NS_ :

BS_:

BU_: VCU BMS DD MM5 PDM MM52 RAND

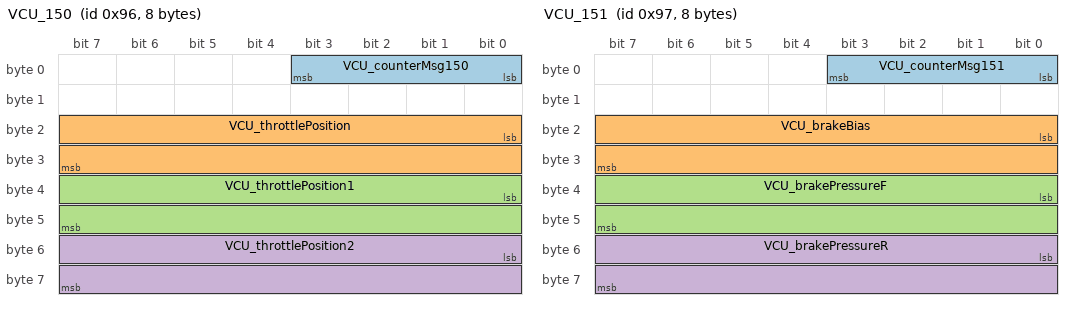
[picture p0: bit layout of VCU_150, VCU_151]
BO_ 150 VCU_150: 8 VCU
 SG_ VCU_counterMsg150 : 0|4@1+ (1,0) [0|15] "" Vector__XXX
 SG_ VCU_throttlePosition : 16|16@1- (0.1,0) [0|100] "%" Vector__XXX
 SG_ VCU_throttlePosition1 : 32|16@1- (0.1,0) [0|100] "%" Vector__XXX
 SG_ VCU_throttlePosition2 : 48|16@1- (0.1,0) [0|100] "%" Vector__XXX

BO_ 151 VCU_151: 8 VCU
 SG_ VCU_counterMsg151 : 0|4@1+ (1,0) [0|15] "" Vector__XXX
 SG_ VCU_brakeBias : 16|16@1- (0.1,0) [-3276.8|3276.7] "%" Vector__XXX
 SG_ VCU_brakePressureF : 32|16@1- (0.1,0) [0|2000] "psi" Vector__XXX
 SG_ VCU_brakePressureR : 48|16@1- (0.1,0) [0|2000] "psi" Vector__XXX

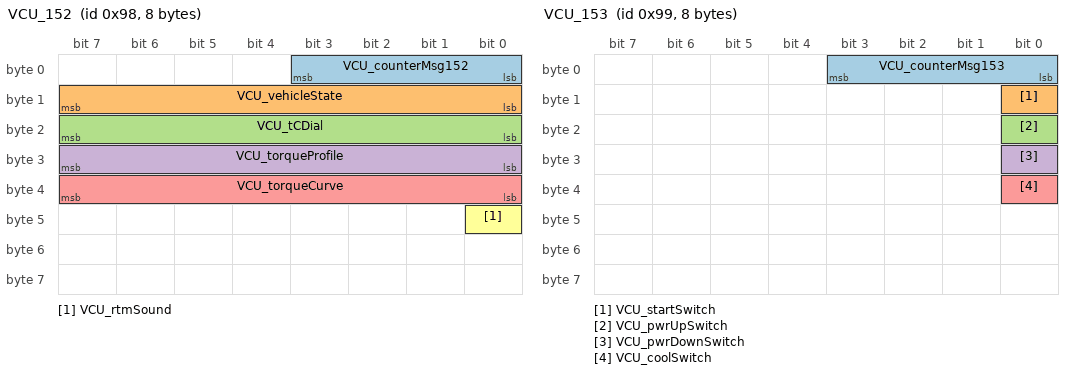
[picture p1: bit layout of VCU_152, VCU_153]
BO_ 152 VCU_152: 8 VCU
 SG_ VCU_counterMsg152 : 0|4@1+ (1,0) [0|15] "" Vector__XXX
 SG_ VCU_vehicleState : 8|8@1+ (1,0) [0|255] "" Vector__XXX
 SG_ VCU_tCDial : 16|8@1+ (1,0) [0|255] "" Vector__XXX
 SG_ VCU_torqueProfile : 24|8@1+ (1,0) [0|255] "" Vector__XXX
 SG_ VCU_torqueCurve : 32|8@1+ (1,0) [0|255] "" Vector__XXX
 SG_ VCU_rtmSound : 40|1@1+ (1,0) [0|1] "" Vector__XXX

BO_ 153 VCU_153: 8 VCU
 SG_ VCU_counterMsg153 : 0|4@1+ (1,0) [0|15] "" Vector__XXX
 SG_ VCU_startSwitch : 8|1@1+ (1,0) [0|1] "" Vector__XXX
 SG_ VCU_pwrUpSwitch : 16|1@1+ (1,0) [0|1] "" Vector__XXX
 SG_ VCU_pwrDownSwitch : 24|1@1+ (1,0) [0|1] "" Vector__XXX
 SG_ VCU_coolSwitch : 32|1@1+ (1,0) [0|1] "" Vector__XXX

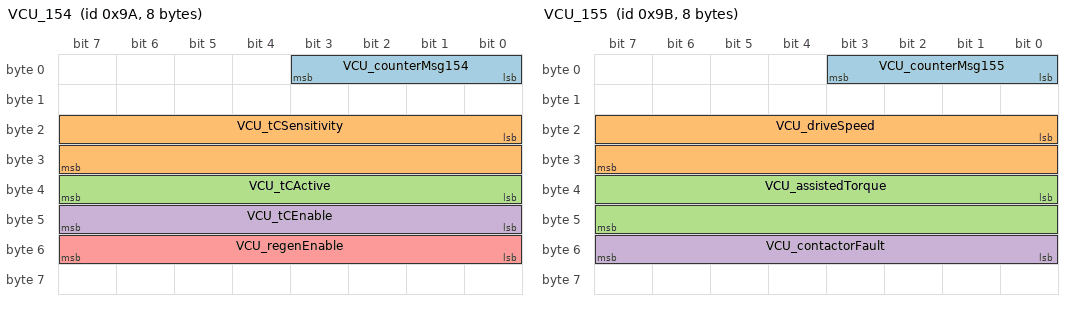
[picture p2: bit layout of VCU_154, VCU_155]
BO_ 154 VCU_154: 8 VCU
 SG_ VCU_counterMsg154 : 0|4@1+ (1,0) [0|15] "" Vector__XXX
 SG_ VCU_tCSensitivity : 16|16@1+ (1,0) [-20|3276.7] "" Vector__XXX
 SG_ VCU_tCActive : 32|8@1+ (1,0) [0|255] "" Vector__XXX
 SG_ VCU_tCEnable : 40|8@1+ (1,0) [0|255] "" Vector__XXX
 SG_ VCU_regenEnable : 48|8@1+ (1,0) [0|255] "" Vector__XXX

BO_ 155 VCU_155: 8 VCU
 SG_ VCU_counterMsg155 : 0|4@1+ (1,0) [0|15] "" Vector__XXX
 SG_ VCU_driveSpeed : 16|16@1- (0.1,0) [-20|3276.7] "mph" Vector__XXX
 SG_ VCU_assistedTorque : 32|16@1- (0.1,0) [-300|300] "Nm" Vector__XXX
 SG_ VCU_contactorFault : 48|8@1+ (1,0) [0|255] "" Vector__XXX

BO_ 156 VCU_156: 8 VCU
 SG_ VCU_counterMsg156 : 0|4@1+ (1,0) [0|15] "" Vector__XXX

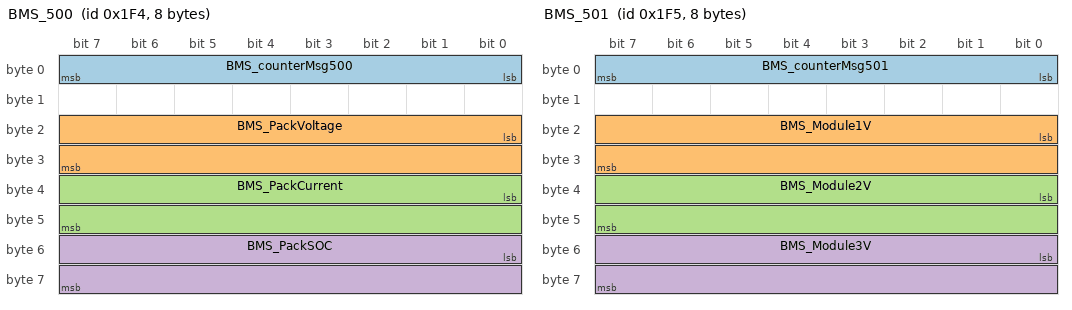
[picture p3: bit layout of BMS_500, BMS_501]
BO_ 500 BMS_500: 8 BMS
 SG_ BMS_counterMsg500 : 0|8@1+ (1,0) [0|15] "" Vector__XXX
 SG_ BMS_PackVoltage : 16|16@1+ (1,0) [-3276|3276] "V" Vector__XXX
 SG_ BMS_PackCurrent : 32|16@1+ (1,0) [-3276|3276] "A" Vector__XXX
 SG_ BMS_PackSOC : 48|16@1+ (1,0) [0|15] "%" Vector__XXX

BO_ 501 BMS_501: 8 BMS
 SG_ BMS_counterMsg501 : 0|8@1+ (1,0) [0|15] "" Vector__XXX
 SG_ BMS_Module1V : 16|16@1+ (1,0) [-3276|3276] "V" Vector__XXX
 SG_ BMS_Module2V : 32|16@1+ (1,0) [-3276|3276] "V" Vector__XXX
 SG_ BMS_Module3V : 48|16@1+ (1,0) [-3276|3276] "V" Vector__XXX

BO_ 502 BMS_502: 8 BMS
 SG_ BMS_counterMsg502 : 0|8@1+ (1,0) [0|15] "" Vector__XXX
 SG_ BMS_Module4V : 16|16@1+ (1,0) [-3276|3276] "V" Vector__XXX
 SG_ BMS_Module5V : 32|16@1+ (1,0) [-3276|3276] "V" Vector__XXX

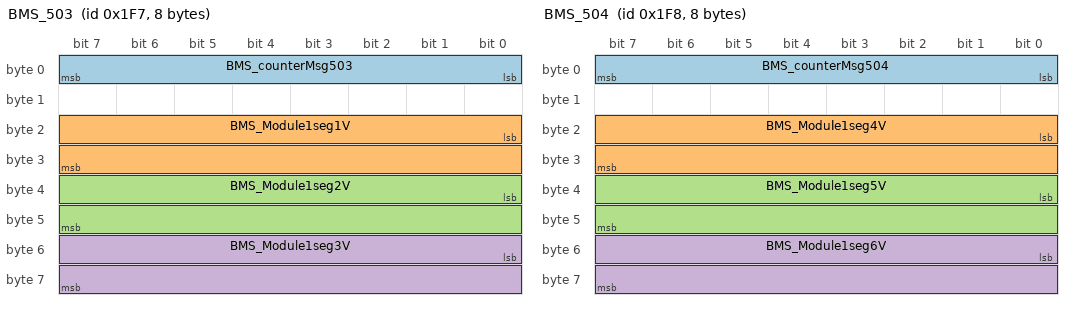
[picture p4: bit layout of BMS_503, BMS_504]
BO_ 503 BMS_503: 8 BMS
 SG_ BMS_counterMsg503 : 0|8@1+ (1,0) [0|15] "" Vector__XXX
 SG_ BMS_Module1seg1V : 16|16@1+ (1,0) [-3276|3276] "V" Vector__XXX
 SG_ BMS_Module1seg2V : 32|16@1+ (1,0) [-3276|3276] "V" Vector__XXX
 SG_ BMS_Module1seg3V : 48|16@1+ (1,0) [-3276|3276] "V" Vector__XXX

BO_ 504 BMS_504: 8 BMS
 SG_ BMS_counterMsg504 : 0|8@1+ (1,0) [0|15] "" Vector__XXX
 SG_ BMS_Module1seg4V : 16|16@1+ (1,0) [-3276|3276] "V" Vector__XXX
 SG_ BMS_Module1seg5V : 32|16@1+ (1,0) [-3276|3276] "V" Vector__XXX
 SG_ BMS_Module1seg6V : 48|16@1+ (1,0) [-3276|3276] "V" Vector__XXX

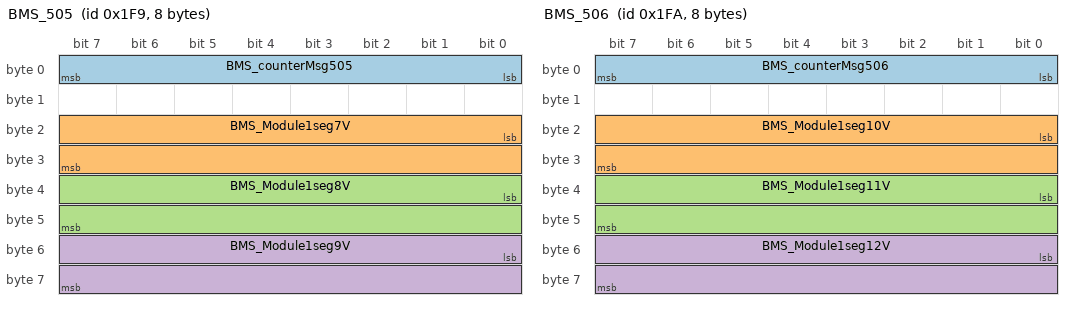
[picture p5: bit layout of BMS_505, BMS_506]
BO_ 505 BMS_505: 8 BMS
 SG_ BMS_counterMsg505 : 0|8@1+ (1,0) [0|15] "" Vector__XXX
 SG_ BMS_Module1seg7V : 16|16@1+ (1,0) [-3276|3276] "V" Vector__XXX
 SG_ BMS_Module1seg8V : 32|16@1+ (1,0) [-3276|3276] "V" Vector__XXX
 SG_ BMS_Module1seg9V : 48|16@1+ (1,0) [-3276|3276] "V" Vector__XXX

BO_ 506 BMS_506: 8 BMS
 SG_ BMS_counterMsg506 : 0|8@1+ (1,0) [0|15] "" Vector__XXX
 SG_ BMS_Module1seg10V : 16|16@1+ (1,0) [-3276|3276] "V" Vector__XXX
 SG_ BMS_Module1seg11V : 32|16@1+ (1,0) [-3276|3276] "V" Vector__XXX
 SG_ BMS_Module1seg12V : 48|16@1+ (1,0) [-3276|3276] "V" Vector__XXX

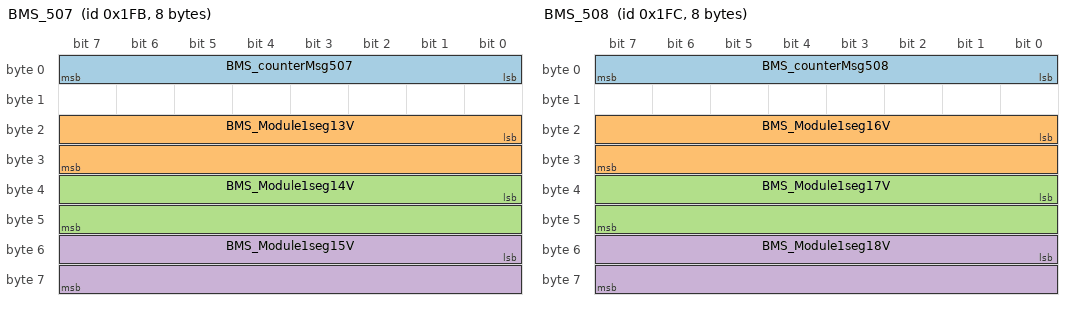
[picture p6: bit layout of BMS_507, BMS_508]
BO_ 507 BMS_507: 8 BMS
 SG_ BMS_counterMsg507 : 0|8@1+ (1,0) [0|15] "" Vector__XXX
 SG_ BMS_Module1seg13V : 16|16@1+ (1,0) [-3276|3276] "V" Vector__XXX
 SG_ BMS_Module1seg14V : 32|16@1+ (1,0) [-3276|3276] "V" Vector__XXX
 SG_ BMS_Module1seg15V : 48|16@1+ (1,0) [-3276|3276] "V" Vector__XXX

BO_ 508 BMS_508: 8 BMS
 SG_ BMS_counterMsg508 : 0|8@1+ (1,0) [0|15] "" Vector__XXX
 SG_ BMS_Module1seg16V : 16|16@1+ (1,0) [-3276|3276] "V" Vector__XXX
 SG_ BMS_Module1seg17V : 32|16@1+ (1,0) [-3276|3276] "V" Vector__XXX
 SG_ BMS_Module1seg18V : 48|16@1+ (1,0) [-3276|3276] "V" Vector__XXX

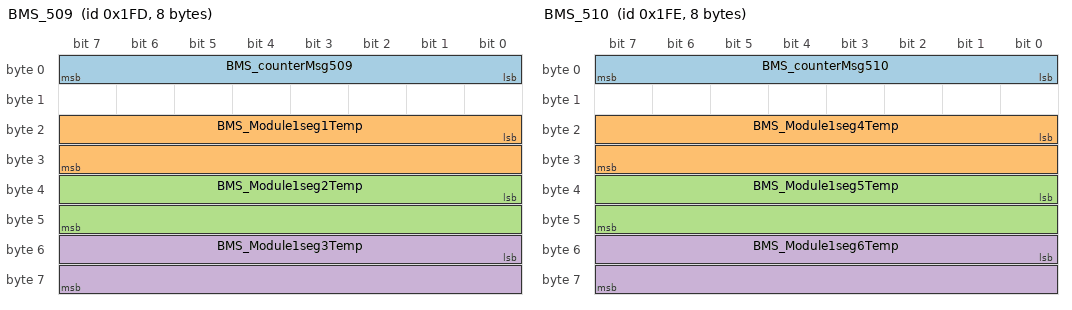
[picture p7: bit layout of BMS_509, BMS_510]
BO_ 509 BMS_509: 8 BMS
 SG_ BMS_counterMsg509 : 0|8@1+ (1,0) [0|15] "" Vector__XXX
 SG_ BMS_Module1seg1Temp : 16|16@1+ (1,0) [-3276|3276] "C" Vector__XXX
 SG_ BMS_Module1seg2Temp : 32|16@1+ (1,0) [-3276|3276] "C" Vector__XXX
 SG_ BMS_Module1seg3Temp : 48|16@1+ (1,0) [-3276|3276] "C" Vector__XXX

BO_ 510 BMS_510: 8 BMS
 SG_ BMS_counterMsg510 : 0|8@1+ (1,0) [0|15] "" Vector__XXX
 SG_ BMS_Module1seg4Temp : 16|16@1+ (1,0) [-3276|3276] "C" Vector__XXX
 SG_ BMS_Module1seg5Temp : 32|16@1+ (1,0) [-3276|3276] "C" Vector__XXX
 SG_ BMS_Module1seg6Temp : 48|16@1+ (1,0) [-3276|3276] "C" Vector__XXX

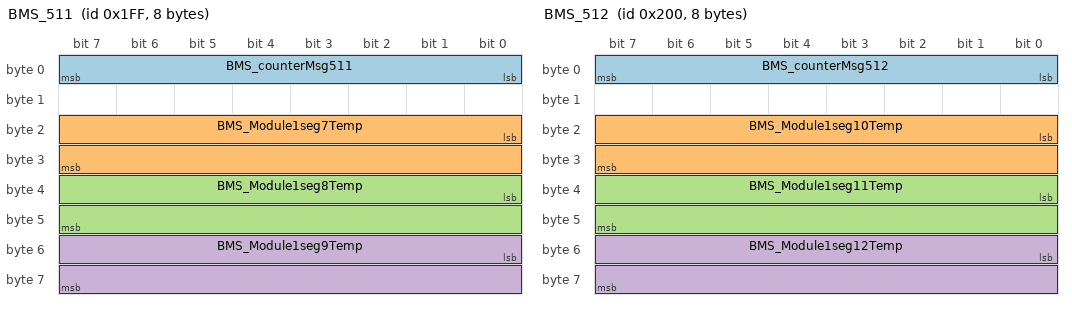
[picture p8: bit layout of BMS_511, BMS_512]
BO_ 511 BMS_511: 8 BMS
 SG_ BMS_counterMsg511 : 0|8@1+ (1,0) [0|15] "" Vector__XXX
 SG_ BMS_Module1seg7Temp : 16|16@1+ (1,0) [-3276|3276] "C" Vector__XXX
 SG_ BMS_Module1seg8Temp : 32|16@1+ (1,0) [-3276|3276] "C" Vector__XXX
 SG_ BMS_Module1seg9Temp : 48|16@1+ (1,0) [-3276|3276] "C" Vector__XXX

BO_ 512 BMS_512: 8 BMS
 SG_ BMS_counterMsg512 : 0|8@1+ (1,0) [0|15] "" Vector__XXX
 SG_ BMS_Module1seg10Temp : 16|16@1+ (1,0) [-3276|3276] "C" Vector__XXX
 SG_ BMS_Module1seg11Temp : 32|16@1+ (1,0) [-3276|3276] "C" Vector__XXX
 SG_ BMS_Module1seg12Temp : 48|16@1+ (1,0) [-3276|3276] "C" Vector__XXX

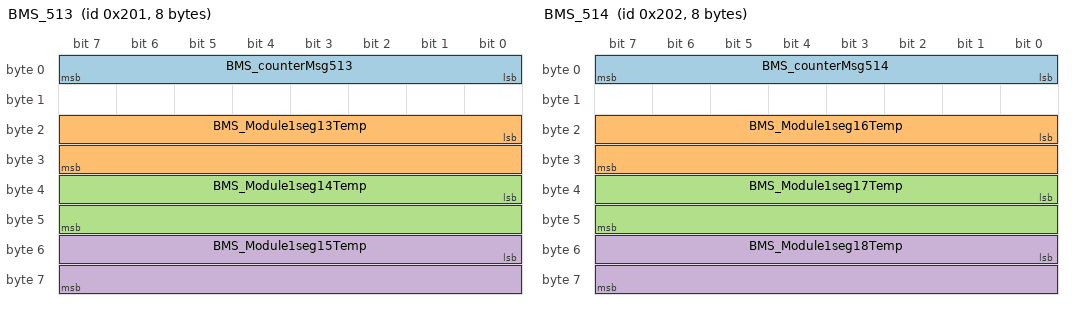
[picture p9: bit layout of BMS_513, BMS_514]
BO_ 513 BMS_513: 8 BMS
 SG_ BMS_counterMsg513 : 0|8@1+ (1,0) [0|15] "" Vector__XXX
 SG_ BMS_Module1seg13Temp : 16|16@1+ (1,0) [-3276|3276] "C" Vector__XXX
 SG_ BMS_Module1seg14Temp : 32|16@1+ (1,0) [-3276|3276] "C" Vector__XXX
 SG_ BMS_Module1seg15Temp : 48|16@1+ (1,0) [-3276|3276] "C" Vector__XXX

BO_ 514 BMS_514: 8 BMS
 SG_ BMS_counterMsg514 : 0|8@1+ (1,0) [0|15] "" Vector__XXX
 SG_ BMS_Module1seg16Temp : 16|16@1+ (1,0) [-3276|3276] "C" Vector__XXX
 SG_ BMS_Module1seg17Temp : 32|16@1+ (1,0) [-3276|3276] "C" Vector__XXX
 SG_ BMS_Module1seg18Temp : 48|16@1+ (1,0) [-3276|3276] "C" Vector__XXX

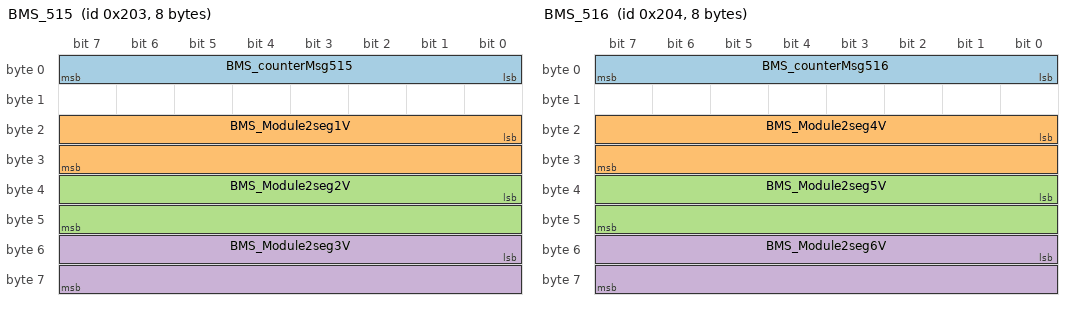
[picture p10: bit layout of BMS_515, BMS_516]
BO_ 515 BMS_515: 8 BMS
 SG_ BMS_counterMsg515 : 0|8@1+ (1,0) [0|15] "" Vector__XXX
 SG_ BMS_Module2seg1V : 16|16@1+ (1,0) [-3276|3276] "V" Vector__XXX
 SG_ BMS_Module2seg2V : 32|16@1+ (1,0) [-3276|3276] "V" Vector__XXX
 SG_ BMS_Module2seg3V : 48|16@1+ (1,0) [-3276|3276] "V" Vector__XXX

BO_ 516 BMS_516: 8 BMS
 SG_ BMS_counterMsg516 : 0|8@1+ (1,0) [0|15] "" Vector__XXX
 SG_ BMS_Module2seg4V : 16|16@1+ (1,0) [-3276|3276] "V" Vector__XXX
 SG_ BMS_Module2seg5V : 32|16@1+ (1,0) [-3276|3276] "V" Vector__XXX
 SG_ BMS_Module2seg6V : 48|16@1+ (1,0) [-3276|3276] "V" Vector__XXX

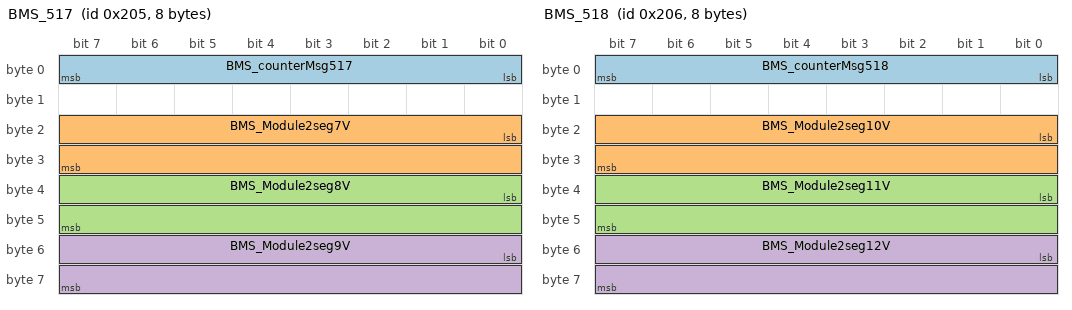
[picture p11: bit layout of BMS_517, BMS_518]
BO_ 517 BMS_517: 8 BMS
 SG_ BMS_counterMsg517 : 0|8@1+ (1,0) [0|15] "" Vector__XXX
 SG_ BMS_Module2seg7V : 16|16@1+ (1,0) [-3276|3276] "V" Vector__XXX
 SG_ BMS_Module2seg8V : 32|16@1+ (1,0) [-3276|3276] "V" Vector__XXX
 SG_ BMS_Module2seg9V : 48|16@1+ (1,0) [-3276|3276] "V" Vector__XXX

BO_ 518 BMS_518: 8 BMS
 SG_ BMS_counterMsg518 : 0|8@1+ (1,0) [0|15] "" Vector__XXX
 SG_ BMS_Module2seg10V : 16|16@1+ (1,0) [-3276|3276] "V" Vector__XXX
 SG_ BMS_Module2seg11V : 32|16@1+ (1,0) [-3276|3276] "V" Vector__XXX
 SG_ BMS_Module2seg12V : 48|16@1+ (1,0) [-3276|3276] "V" Vector__XXX

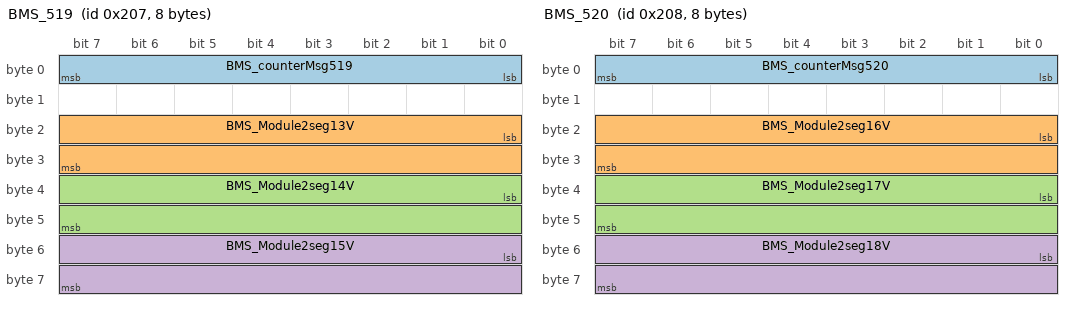
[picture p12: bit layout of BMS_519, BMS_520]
BO_ 519 BMS_519: 8 BMS
 SG_ BMS_counterMsg519 : 0|8@1+ (1,0) [0|15] "" Vector__XXX
 SG_ BMS_Module2seg13V : 16|16@1+ (1,0) [-3276|3276] "V" Vector__XXX
 SG_ BMS_Module2seg14V : 32|16@1+ (1,0) [-3276|3276] "V" Vector__XXX
 SG_ BMS_Module2seg15V : 48|16@1+ (1,0) [-3276|3276] "V" Vector__XXX

BO_ 520 BMS_520: 8 BMS
 SG_ BMS_counterMsg520 : 0|8@1+ (1,0) [0|15] "" Vector__XXX
 SG_ BMS_Module2seg16V : 16|16@1+ (1,0) [-3276|3276] "V" Vector__XXX
 SG_ BMS_Module2seg17V : 32|16@1+ (1,0) [-3276|3276] "V" Vector__XXX
 SG_ BMS_Module2seg18V : 48|16@1+ (1,0) [-3276|3276] "V" Vector__XXX

BO_ 521 BMS_521: 8 BMS
 SG_ BMS_counterMsg521 : 0|8@1+ (1,0) [0|15] "" Vector__XXX
 SG_ BMS_Module2seg1Temp : 16|16@1+ (1,0) [-3276|3276] "C" Vector__XXX
 SG_ BMS_Module2seg2Temp : 32|16@1+ (1,0) [-3276|3276] "C" Vector__XXX
 SG_ BMS_Module2seg3Temp : 48|16@1+ (1,0) [-3276|3276] "C" Vector__XXX

BO_ 522 BMS_522: 8 BMS
 SG_ BMS_counterMsg522 : 0|8@1+ (1,0) [0|15] "" Vector__XXX
 SG_ BMS_Module2seg4Temp : 16|16@1+ (1,0) [-3276|3276] "C" Vector__XXX
 SG_ BMS_Module2seg5Temp : 32|16@1+ (1,0) [-3276|3276] "C" Vector__XXX
 SG_ BMS_Module2seg6Temp : 48|16@1+ (1,0) [-3276|3276] "C" Vector__XXX

BO_ 523 BMS_523: 8 BMS
 SG_ BMS_counterMsg523 : 0|8@1+ (1,0) [0|15] "" Vector__XXX
 SG_ BMS_Module2seg7Temp : 16|16@1+ (1,0) [-3276|3276] "C" Vector__XXX
 SG_ BMS_Module2seg8Temp : 32|16@1+ (1,0) [-3276|3276] "C" Vector__XXX
 SG_ BMS_Module2seg9Temp : 48|16@1+ (1,0) [-3276|3276] "C" Vector__XXX

BO_ 524 BMS_524: 8 BMS
 SG_ BMS_counterMsg524 : 0|8@1+ (1,0) [0|15] "" Vector__XXX
 SG_ BMS_Module2seg10Temp : 16|16@1+ (1,0) [-3276|3276] "C" Vector__XXX
 SG_ BMS_Module2seg11Temp : 32|16@1+ (1,0) [-3276|3276] "C" Vector__XXX
 SG_ BMS_Module2seg12Temp : 48|16@1+ (1,0) [-3276|3276] "C" Vector__XXX

BO_ 525 BMS_525: 8 BMS
 SG_ BMS_counterMsg525 : 0|8@1+ (1,0) [0|15] "" Vector__XXX
 SG_ BMS_Module2seg13Temp : 16|16@1+ (1,0) [-3276|3276] "C" Vector__XXX
 SG_ BMS_Module2seg14Temp : 32|16@1+ (1,0) [-3276|3276] "C" Vector__XXX
 SG_ BMS_Module2seg15Temp : 48|16@1+ (1,0) [-3276|3276] "C" Vector__XXX

BO_ 526 BMS_526: 8 BMS
 SG_ BMS_counterMsg526 : 0|8@1+ (1,0) [0|15] "" Vector__XXX
 SG_ BMS_Module2seg16Temp : 16|16@1+ (1,0) [-3276|3276] "C" Vector__XXX
 SG_ BMS_Module2seg17Temp : 32|16@1+ (1,0) [-3276|3276] "C" Vector__XXX
 SG_ BMS_Module2seg18Temp : 48|16@1+ (1,0) [-3276|3276] "C" Vector__XXX

BO_ 527 BMS_527: 8 BMS
 SG_ BMS_counterMsg527 : 0|8@1+ (1,0) [0|15] "" Vector__XXX
 SG_ BMS_Module3seg1V : 16|16@1+ (1,0) [-3276|3276] "V" Vector__XXX
 SG_ BMS_Module3seg2V : 32|16@1+ (1,0) [-3276|3276] "V" Vector__XXX
 SG_ BMS_Module3seg3V : 48|16@1+ (1,0) [-3276|3276] "V" Vector__XXX

BO_ 528 BMS_528: 8 BMS
 SG_ BMS_counterMsg528 : 0|8@1+ (1,0) [0|15] "" Vector__XXX
 SG_ BMS_Module3seg4V : 16|16@1+ (1,0) [-3276|3276] "V" Vector__XXX
 SG_ BMS_Module3seg5V : 32|16@1+ (1,0) [-3276|3276] "V" Vector__XXX
 SG_ BMS_Module3seg6V : 48|16@1+ (1,0) [-3276|3276] "V" Vector__XXX

BO_ 529 BMS_529: 8 BMS
 SG_ BMS_counterMsg529 : 0|8@1+ (1,0) [0|15] "" Vector__XXX
 SG_ BMS_Module3seg7V : 16|16@1+ (1,0) [-3276|3276] "V" Vector__XXX
 SG_ BMS_Module3seg8V : 32|16@1+ (1,0) [-3276|3276] "V" Vector__XXX
 SG_ BMS_Module3seg9V : 48|16@1+ (1,0) [-3276|3276] "V" Vector__XXX

BO_ 530 BMS_530: 8 BMS
 SG_ BMS_counterMsg530 : 0|8@1+ (1,0) [0|15] "" Vector__XXX
 SG_ BMS_Module3seg10V : 16|16@1+ (1,0) [-3276|3276] "V" Vector__XXX
 SG_ BMS_Module3seg11V : 32|16@1+ (1,0) [-3276|3276] "V" Vector__XXX
 SG_ BMS_Module3seg12V : 48|16@1+ (1,0) [-3276|3276] "V" Vector__XXX

BO_ 531 BMS_531: 8 BMS
 SG_ BMS_counterMsg531 : 0|8@1+ (1,0) [0|15] "" Vector__XXX
 SG_ BMS_Module3seg13V : 16|16@1+ (1,0) [-3276|3276] "V" Vector__XXX
 SG_ BMS_Module3seg14V : 32|16@1+ (1,0) [-3276|3276] "V" Vector__XXX
 SG_ BMS_Module3seg15V : 48|16@1+ (1,0) [-3276|3276] "V" Vector__XXX

BO_ 532 BMS_532: 8 BMS
 SG_ BMS_counterMsg532 : 0|8@1+ (1,0) [0|15] "" Vector__XXX
 SG_ BMS_Module3seg16V : 16|16@1+ (1,0) [-3276|3276] "V" Vector__XXX
 SG_ BMS_Module3seg17V : 32|16@1+ (1,0) [-3276|3276] "V" Vector__XXX
 SG_ BMS_Module3seg18V : 48|16@1+ (1,0) [-3276|3276] "V" Vector__XXX

BO_ 533 BMS_533: 8 BMS
 SG_ BMS_counterMsg533 : 0|8@1+ (1,0) [0|15] "" Vector__XXX
 SG_ BMS_Module3seg1Temp : 16|16@1+ (1,0) [-3276|3276] "C" Vector__XXX
 SG_ BMS_Module3seg2Temp : 32|16@1+ (1,0) [-3276|3276] "C" Vector__XXX
 SG_ BMS_Module3seg3Temp : 48|16@1+ (1,0) [-3276|3276] "C" Vector__XXX

BO_ 534 BMS_534: 8 BMS
 SG_ BMS_counterMsg534 : 0|8@1+ (1,0) [0|15] "" Vector__XXX
 SG_ BMS_Module3seg4Temp : 16|16@1+ (1,0) [-3276|3276] "C" Vector__XXX
 SG_ BMS_Module3seg5Temp : 32|16@1+ (1,0) [-3276|3276] "C" Vector__XXX
 SG_ BMS_Module3seg6Temp : 48|16@1+ (1,0) [-3276|3276] "C" Vector__XXX

BO_ 535 BMS_535: 8 BMS
 SG_ BMS_counterMsg535 : 0|8@1+ (1,0) [0|15] "" Vector__XXX
 SG_ BMS_Module3seg7Temp : 16|16@1+ (1,0) [-3276|3276] "C" Vector__XXX
 SG_ BMS_Module3seg8Temp : 32|16@1+ (1,0) [-3276|3276] "C" Vector__XXX
 SG_ BMS_Module3seg9Temp : 48|16@1+ (1,0) [-3276|3276] "C" Vector__XXX

BO_ 536 BMS_536: 8 BMS
 SG_ BMS_counterMsg536 : 0|8@1+ (1,0) [0|15] "" Vector__XXX
 SG_ BMS_Module3seg10Temp : 16|16@1+ (1,0) [-3276|3276] "C" Vector__XXX
 SG_ BMS_Module3seg11Temp : 32|16@1+ (1,0) [-3276|3276] "C" Vector__XXX
 SG_ BMS_Module3seg12Temp : 48|16@1+ (1,0) [-3276|3276] "C" Vector__XXX

BO_ 537 BMS_537: 8 BMS
 SG_ BMS_counterMsg537 : 0|8@1+ (1,0) [0|15] "" Vector__XXX
 SG_ BMS_Module3seg13Temp : 16|16@1+ (1,0) [-3276|3276] "C" Vector__XXX
 SG_ BMS_Module3seg14Temp : 32|16@1+ (1,0) [-3276|3276] "C" Vector__XXX
 SG_ BMS_Module3seg15Temp : 48|16@1+ (1,0) [-3276|3276] "C" Vector__XXX

BO_ 538 BMS_538: 8 BMS
 SG_ BMS_counterMsg538 : 0|8@1+ (1,0) [0|15] "" Vector__XXX
 SG_ BMS_Module3seg16Temp : 16|16@1+ (1,0) [-3276|3276] "C" Vector__XXX
 SG_ BMS_Module3seg17Temp : 32|16@1+ (1,0) [-3276|3276] "C" Vector__XXX
 SG_ BMS_Module3seg18Temp : 48|16@1+ (1,0) [-3276|3276] "C" Vector__XXX

BO_ 539 BMS_539: 8 BMS
 SG_ BMS_counterMsg539 : 0|8@1+ (1,0) [0|15] "" Vector__XXX
 SG_ BMS_Module4seg1V : 16|16@1+ (1,0) [-3276|3276] "V" Vector__XXX
 SG_ BMS_Module4seg2V : 32|16@1+ (1,0) [-3276|3276] "V" Vector__XXX
 SG_ BMS_Module4seg3V : 48|16@1+ (1,0) [-3276|3276] "V" Vector__XXX

BO_ 540 BMS_540: 8 BMS
 SG_ BMS_counterMsg540 : 0|8@1+ (1,0) [0|15] "" Vector__XXX
 SG_ BMS_Module4seg4V : 16|16@1+ (1,0) [-3276|3276] "V" Vector__XXX
 SG_ BMS_Module4seg5V : 32|16@1+ (1,0) [-3276|3276] "V" Vector__XXX
 SG_ BMS_Module4seg6V : 48|16@1+ (1,0) [-3276|3276] "V" Vector__XXX

BO_ 541 BMS_541: 8 BMS
 SG_ BMS_counterMsg541 : 0|8@1+ (1,0) [0|15] "" Vector__XXX
 SG_ BMS_Module4seg7V : 16|16@1+ (1,0) [-3276|3276] "V" Vector__XXX
 SG_ BMS_Module4seg8V : 32|16@1+ (1,0) [-3276|3276] "V" Vector__XXX
 SG_ BMS_Module4seg9V : 48|16@1+ (1,0) [-3276|3276] "V" Vector__XXX

BO_ 542 BMS_542: 8 BMS
 SG_ BMS_counterMsg542 : 0|8@1+ (1,0) [0|15] "" Vector__XXX
 SG_ BMS_Module4seg10V : 16|16@1+ (1,0) [-3276|3276] "V" Vector__XXX
 SG_ BMS_Module4seg11V : 32|16@1+ (1,0) [-3276|3276] "V" Vector__XXX
 SG_ BMS_Module4seg12V : 48|16@1+ (1,0) [-3276|3276] "V" Vector__XXX

BO_ 543 BMS_543: 8 BMS
 SG_ BMS_counterMsg543 : 0|8@1+ (1,0) [0|15] "" Vector__XXX
 SG_ BMS_Module4seg13V : 16|16@1+ (1,0) [-3276|3276] "V" Vector__XXX
 SG_ BMS_Module4seg14V : 32|16@1+ (1,0) [-3276|3276] "V" Vector__XXX
 SG_ BMS_Module4seg15V : 48|16@1+ (1,0) [-3276|3276] "V" Vector__XXX

BO_ 544 BMS_544: 8 BMS
 SG_ BMS_counterMsg544 : 0|8@1+ (1,0) [0|15] "" Vector__XXX
 SG_ BMS_Module4seg16V : 16|16@1+ (1,0) [-3276|3276] "V" Vector__XXX
 SG_ BMS_Module4seg17V : 32|16@1+ (1,0) [-3276|3276] "V" Vector__XXX
 SG_ BMS_Module4seg18V : 48|16@1+ (1,0) [-3276|3276] "V" Vector__XXX

BO_ 545 BMS_545: 8 BMS
 SG_ BMS_counterMsg545 : 0|8@1+ (1,0) [0|15] "" Vector__XXX
 SG_ BMS_Module4seg1Temp : 16|16@1+ (1,0) [-3276|3276] "C" Vector__XXX
 SG_ BMS_Module4seg2Temp : 32|16@1+ (1,0) [-3276|3276] "C" Vector__XXX
 SG_ BMS_Module4seg3Temp : 48|16@1+ (1,0) [-3276|3276] "C" Vector__XXX

BO_ 546 BMS_546: 8 BMS
 SG_ BMS_counterMsg546 : 0|8@1+ (1,0) [0|15] "" Vector__XXX
 SG_ BMS_Module4seg4Temp : 16|16@1+ (1,0) [-3276|3276] "C" Vector__XXX
 SG_ BMS_Module4seg5Temp : 32|16@1+ (1,0) [-3276|3276] "C" Vector__XXX
 SG_ BMS_Module4seg6Temp : 48|16@1+ (1,0) [-3276|3276] "C" Vector__XXX

BO_ 547 BMS_547: 8 BMS
 SG_ BMS_counterMsg547 : 0|8@1+ (1,0) [0|15] "" Vector__XXX
 SG_ BMS_Module4seg7Temp : 16|16@1+ (1,0) [-3276|3276] "C" Vector__XXX
 SG_ BMS_Module4seg8Temp : 32|16@1+ (1,0) [-3276|3276] "C" Vector__XXX
 SG_ BMS_Module4seg9Temp : 48|16@1+ (1,0) [-3276|3276] "C" Vector__XXX

BO_ 548 BMS_548: 8 BMS
 SG_ BMS_counterMsg548 : 0|8@1+ (1,0) [0|15] "" Vector__XXX
 SG_ BMS_Module4seg10Temp : 16|16@1+ (1,0) [-3276|3276] "C" Vector__XXX
 SG_ BMS_Module4seg11Temp : 32|16@1+ (1,0) [-3276|3276] "C" Vector__XXX
 SG_ BMS_Module4seg12Temp : 48|16@1+ (1,0) [-3276|3276] "C" Vector__XXX

BO_ 549 BMS_549: 8 BMS
 SG_ BMS_counterMsg549 : 0|8@1+ (1,0) [0|15] "" Vector__XXX
 SG_ BMS_Module4seg13Temp : 16|16@1+ (1,0) [-3276|3276] "C" Vector__XXX
 SG_ BMS_Module4seg14Temp : 32|16@1+ (1,0) [-3276|3276] "C" Vector__XXX
 SG_ BMS_Module4seg15Temp : 48|16@1+ (1,0) [-3276|3276] "C" Vector__XXX

BO_ 550 BMS_550: 8 BMS
 SG_ BMS_counterMsg550 : 0|8@1+ (1,0) [0|15] "" Vector__XXX
 SG_ BMS_Module4seg16Temp : 16|16@1+ (1,0) [-3276|3276] "C" Vector__XXX
 SG_ BMS_Module4seg17Temp : 32|16@1+ (1,0) [-3276|3276] "C" Vector__XXX
 SG_ BMS_Module4seg18Temp : 48|16@1+ (1,0) [-3276|3276] "C" Vector__XXX

BO_ 551 BMS_551: 8 BMS
 SG_ BMS_counterMsg551 : 0|8@1+ (1,0) [0|15] "" Vector__XXX
 SG_ BMS_Module5seg1V : 16|16@1+ (1,0) [-3276|3276] "V" Vector__XXX
 SG_ BMS_Module5seg2V : 32|16@1+ (1,0) [-3276|3276] "V" Vector__XXX
 SG_ BMS_Module5seg3V : 48|16@1+ (1,0) [-3276|3276] "V" Vector__XXX

BO_ 552 BMS_552: 8 BMS
 SG_ BMS_counterMsg552 : 0|8@1+ (1,0) [0|15] "" Vector__XXX
 SG_ BMS_Module5seg4V : 16|16@1+ (1,0) [-3276|3276] "V" Vector__XXX
 SG_ BMS_Module5seg5V : 32|16@1+ (1,0) [-3276|3276] "V" Vector__XXX
 SG_ BMS_Module5seg6V : 48|16@1+ (1,0) [-3276|3276] "V" Vector__XXX

BO_ 553 BMS_553: 8 BMS
 SG_ BMS_counterMsg553 : 0|8@1+ (1,0) [0|15] "" Vector__XXX
 SG_ BMS_Module5seg7V : 16|16@1+ (1,0) [-3276|3276] "V" Vector__XXX
 SG_ BMS_Module5seg8V : 32|16@1+ (1,0) [-3276|3276] "V" Vector__XXX
 SG_ BMS_Module5seg9V : 48|16@1+ (1,0) [-3276|3276] "V" Vector__XXX

BO_ 554 BMS_554: 8 BMS
 SG_ BMS_counterMsg554 : 0|8@1+ (1,0) [0|15] "" Vector__XXX
 SG_ BMS_Module5seg10V : 16|16@1+ (1,0) [-3276|3276] "V" Vector__XXX
 SG_ BMS_Module5seg11V : 32|16@1+ (1,0) [-3276|3276] "V" Vector__XXX
 SG_ BMS_Module5seg12V : 48|16@1+ (1,0) [-3276|3276] "V" Vector__XXX

BO_ 555 BMS_555: 8 BMS
 SG_ BMS_counterMsg555 : 0|8@1+ (1,0) [0|15] "" Vector__XXX
 SG_ BMS_Module5seg13V : 16|16@1+ (1,0) [-3276|3276] "V" Vector__XXX
 SG_ BMS_Module5seg14V : 32|16@1+ (1,0) [-3276|3276] "V" Vector__XXX
 SG_ BMS_Module5seg15V : 48|16@1+ (1,0) [-3276|3276] "V" Vector__XXX

BO_ 556 BMS_556: 8 BMS
 SG_ BMS_counterMsg556 : 0|8@1+ (1,0) [0|15] "" Vector__XXX
 SG_ BMS_Module5seg16V : 16|16@1+ (1,0) [-3276|3276] "V" Vector__XXX
 SG_ BMS_Module5seg17V : 32|16@1+ (1,0) [-3276|3276] "V" Vector__XXX
 SG_ BMS_Module5seg18V : 48|16@1+ (1,0) [-3276|3276] "V" Vector__XXX

BO_ 557 BMS_557: 8 BMS
 SG_ BMS_counterMsg557 : 0|8@1+ (1,0) [0|15] "" Vector__XXX
 SG_ BMS_Module5seg1Temp : 16|16@1+ (1,0) [-3276|3276] "C" Vector__XXX
 SG_ BMS_Module5seg2Temp : 32|16@1+ (1,0) [-3276|3276] "C" Vector__XXX
 SG_ BMS_Module5seg3Temp : 48|16@1+ (1,0) [-3276|3276] "C" Vector__XXX

BO_ 558 BMS_558: 8 BMS
 SG_ BMS_counterMsg558 : 0|8@1+ (1,0) [0|15] "" Vector__XXX
 SG_ BMS_Module5seg4Temp : 16|16@1+ (1,0) [-3276|3276] "C" Vector__XXX
 SG_ BMS_Module5seg5Temp : 32|16@1+ (1,0) [-3276|3276] "C" Vector__XXX
 SG_ BMS_Module5seg6Temp : 48|16@1+ (1,0) [-3276|3276] "C" Vector__XXX

BO_ 559 BMS_559: 8 BMS
 SG_ BMS_counterMsg559 : 0|8@1+ (1,0) [0|15] "" Vector__XXX
 SG_ BMS_Module5seg7Temp : 16|16@1+ (1,0) [-3276|3276] "C" Vector__XXX
 SG_ BMS_Module5seg8Temp : 32|16@1+ (1,0) [-3276|3276] "C" Vector__XXX
 SG_ BMS_Module5seg9Temp : 48|16@1+ (1,0) [-3276|3276] "C" Vector__XXX

BO_ 560 BMS_560: 8 BMS
 SG_ BMS_counterMsg560 : 0|8@1+ (1,0) [0|15] "" Vector__XXX
 SG_ BMS_Module5seg10Temp : 16|16@1+ (1,0) [-3276|3276] "C" Vector__XXX
 SG_ BMS_Module5seg11Temp : 32|16@1+ (1,0) [-3276|3276] "C" Vector__XXX
 SG_ BMS_Module5seg12Temp : 48|16@1+ (1,0) [-3276|3276] "C" Vector__XXX

BO_ 561 BMS_561: 8 BMS
 SG_ BMS_counterMsg561 : 0|8@1+ (1,0) [0|15] "" Vector__XXX
 SG_ BMS_Module5seg13Temp : 16|16@1+ (1,0) [-3276|3276] "C" Vector__XXX
 SG_ BMS_Module5seg14Temp : 32|16@1+ (1,0) [-3276|3276] "C" Vector__XXX
 SG_ BMS_Module5seg15Temp : 48|16@1+ (1,0) [-3276|3276] "C" Vector__XXX

BO_ 562 BMS_562: 8 BMS
 SG_ BMS_counterMsg562 : 0|8@1+ (1,0) [0|15] "" Vector__XXX
 SG_ BMS_Module5seg16Temp : 16|16@1+ (1,0) [-3276|3276] "C" Vector__XXX
 SG_ BMS_Module5seg17Temp : 32|16@1+ (1,0) [-3276|3276] "C" Vector__XXX
 SG_ BMS_Module5seg18Temp : 48|16@1+ (1,0) [-3276|3276] "C" Vector__XXX

BO_ 250 DD_250: 8 DD
 SG_ DD_counterMsg250 : 0|4@1+ (1,0) [0|15] "" Vector__XXX
 SG_ DD_boardTemp : 16|16@1- (0.1,0) [0|150] "degC" Vector__XXX
 SG_ DD_teensyTemp : 32|16@1- (0.1,0) [0|150] "degC" Vector__XXX

BO_ 372 MM5_372: 8 MM5
 SG_ MM5_yawRate : 0|16@1+ (0.005,-163.9) [0|0] "deg/sec" Vector__XXX
 SG_ MM5_ay : 32|16@1+ (0.0001274,-4.1745795) [0|0] "g" Vector__XXX

BO_ 376 MM5_376: 8 MM5
 SG_ MM5_rollRate : 0|16@1+ (-0.005,163.9) [0|0] "deg/sec" Vector__XXX
 SG_ MM5_ax : 32|16@1+ (-0.0001274,4.1745795) [0|0] "g" Vector__XXX

BO_ 380 MM5_380: 8 MM5
 SG_ MM5_az : 32|16@1+ (-0.0001274,4.1745795) [0|0] "g" Vector__XXX

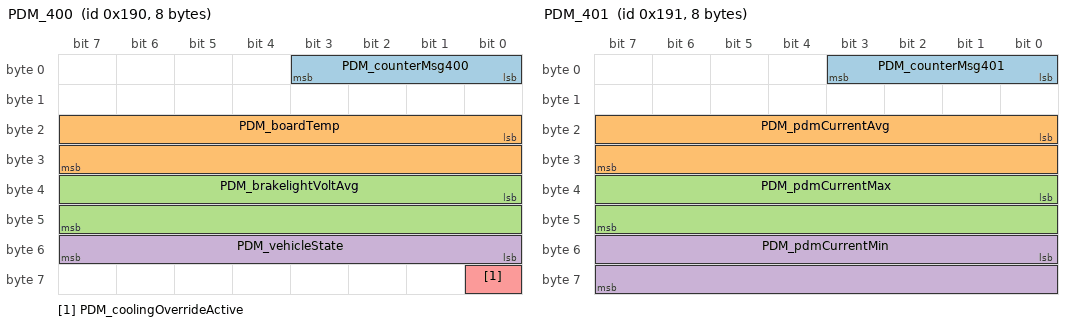
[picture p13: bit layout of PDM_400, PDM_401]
BO_ 400 PDM_400: 8 PDM
 SG_ PDM_counterMsg400 : 0|4@1+ (1,0) [0|15] "" Vector__XXX
 SG_ PDM_boardTemp : 16|16@1- (0.1,0) [-5|100] "degC" Vector__XXX
 SG_ PDM_brakelightVoltAvg : 32|16@1- (0.001,0) [-5|100] "V" Vector__XXX
 SG_ PDM_vehicleState : 48|8@1- (1,0) [0|3] "" Vector__XXX
 SG_ PDM_coolingOverrideActive : 56|1@1+ (1,0) [0|0] "bool" Vector__XXX

BO_ 401 PDM_401: 8 PDM
 SG_ PDM_counterMsg401 : 0|4@1+ (1,0) [0|15] "" Vector__XXX
 SG_ PDM_pdmCurrentAvg : 16|16@1- (0.01,0) [-5|20] "A" Vector__XXX
 SG_ PDM_pdmCurrentMax : 32|16@1- (0.01,0) [-5|20] "A" Vector__XXX
 SG_ PDM_pdmCurrentMin : 48|16@1- (0.01,0) [-5|20] "A" Vector__XXX

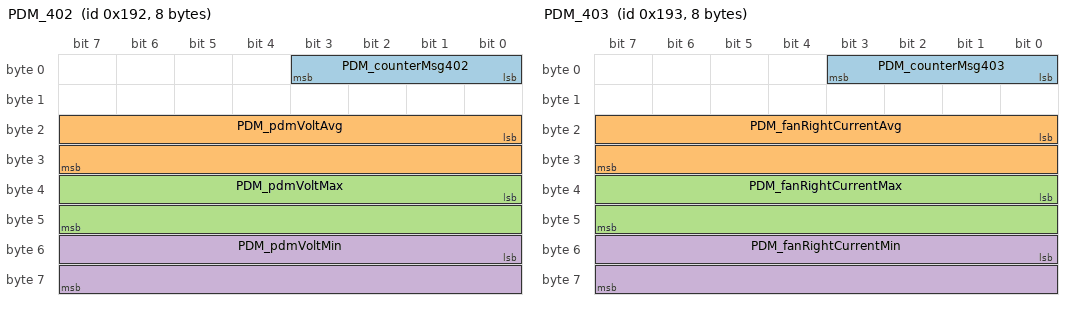
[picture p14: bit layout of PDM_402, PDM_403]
BO_ 402 PDM_402: 8 PDM
 SG_ PDM_counterMsg402 : 0|4@1+ (1,0) [0|15] "" Vector__XXX
 SG_ PDM_pdmVoltAvg : 16|16@1- (0.001,0) [-5|20] "V" Vector__XXX
 SG_ PDM_pdmVoltMax : 32|16@1- (0.001,0) [-5|20] "V" Vector__XXX
 SG_ PDM_pdmVoltMin : 48|16@1- (0.001,0) [-5|20] "V" Vector__XXX

BO_ 403 PDM_403: 8 PDM
 SG_ PDM_counterMsg403 : 0|4@1+ (1,0) [0|15] "" Vector__XXX
 SG_ PDM_fanRightCurrentAvg : 16|16@1- (0.01,0) [-5|20] "A" Vector__XXX
 SG_ PDM_fanRightCurrentMax : 32|16@1- (0.01,0) [-5|20] "A" Vector__XXX
 SG_ PDM_fanRightCurrentMin : 48|16@1- (0.01,0) [-5|20] "A" Vector__XXX

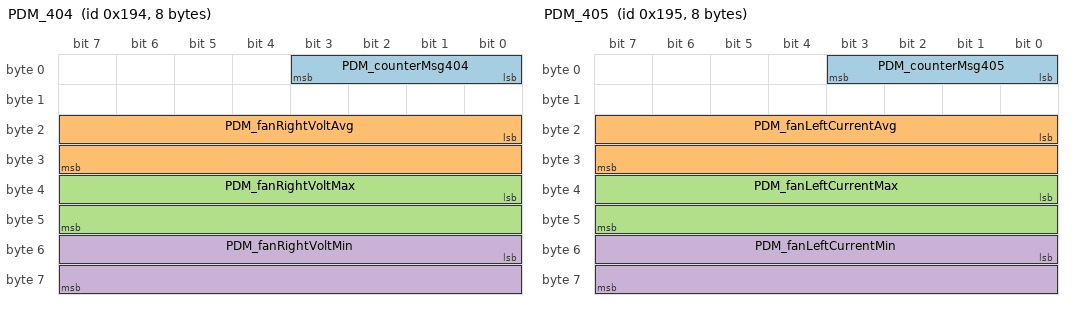
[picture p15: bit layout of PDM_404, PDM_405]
BO_ 404 PDM_404: 8 PDM
 SG_ PDM_counterMsg404 : 0|4@1+ (1,0) [0|15] "" Vector__XXX
 SG_ PDM_fanRightVoltAvg : 16|16@1- (0.001,0) [-5|20] "V" Vector__XXX
 SG_ PDM_fanRightVoltMax : 32|16@1- (0.001,0) [-5|20] "V" Vector__XXX
 SG_ PDM_fanRightVoltMin : 48|16@1- (0.001,0) [-5|20] "V" Vector__XXX

BO_ 405 PDM_405: 8 PDM
 SG_ PDM_counterMsg405 : 0|4@1+ (1,0) [0|15] "" Vector__XXX
 SG_ PDM_fanLeftCurrentAvg : 16|16@1- (0.01,0) [-5|20] "A" Vector__XXX
 SG_ PDM_fanLeftCurrentMax : 32|16@1- (0.01,0) [-5|20] "A" Vector__XXX
 SG_ PDM_fanLeftCurrentMin : 48|16@1- (0.01,0) [-5|20] "A" Vector__XXX

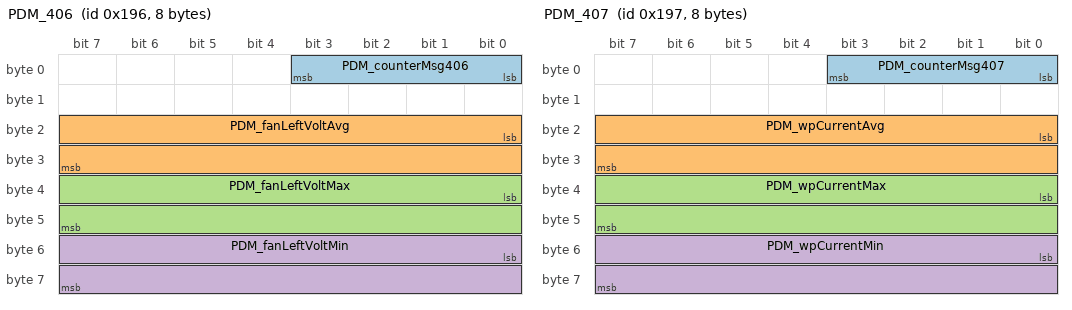
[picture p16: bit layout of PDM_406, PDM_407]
BO_ 406 PDM_406: 8 PDM
 SG_ PDM_counterMsg406 : 0|4@1+ (1,0) [0|15] "" Vector__XXX
 SG_ PDM_fanLeftVoltAvg : 16|16@1- (0.001,0) [-5|20] "V" Vector__XXX
 SG_ PDM_fanLeftVoltMax : 32|16@1- (0.001,0) [-5|20] "V" Vector__XXX
 SG_ PDM_fanLeftVoltMin : 48|16@1- (0.001,0) [-5|20] "V" Vector__XXX

BO_ 407 PDM_407: 8 PDM
 SG_ PDM_counterMsg407 : 0|4@1+ (1,0) [0|15] "" Vector__XXX
 SG_ PDM_wpCurrentAvg : 16|16@1- (0.01,0) [-5|20] "A" Vector__XXX
 SG_ PDM_wpCurrentMax : 32|16@1- (0.01,0) [-5|20] "A" Vector__XXX
 SG_ PDM_wpCurrentMin : 48|16@1- (0.01,0) [-5|20] "A" Vector__XXX

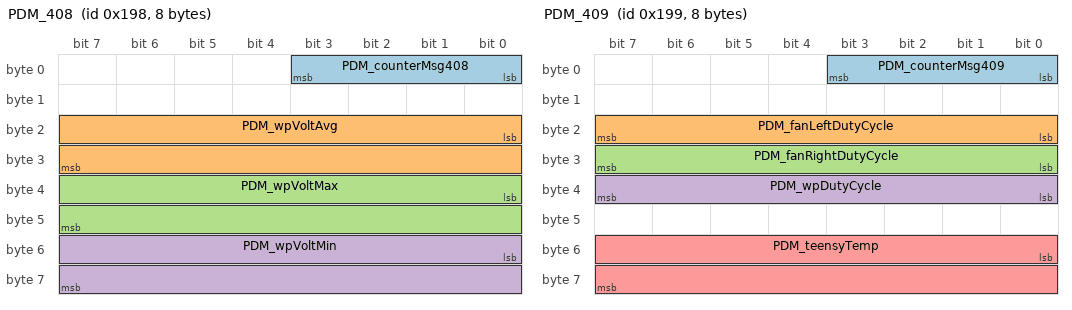
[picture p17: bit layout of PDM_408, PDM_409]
BO_ 408 PDM_408: 8 PDM
 SG_ PDM_counterMsg408 : 0|4@1+ (1,0) [0|15] "" Vector__XXX
 SG_ PDM_wpVoltAvg : 16|16@1- (0.001,0) [-5|20] "V" Vector__XXX
 SG_ PDM_wpVoltMax : 32|16@1- (0.001,0) [-5|20] "V" Vector__XXX
 SG_ PDM_wpVoltMin : 48|16@1- (0.001,0) [-5|20] "V" Vector__XXX

BO_ 409 PDM_409: 8 PDM
 SG_ PDM_counterMsg409 : 0|4@1+ (1,0) [0|15] "" Vector__XXX
 SG_ PDM_fanLeftDutyCycle : 16|8@1+ (1,0) [0|100] "Duty Cycle" Vector__XXX
 SG_ PDM_fanRightDutyCycle : 24|8@1+ (1,0) [0|100] "Duty Cycle" Vector__XXX
 SG_ PDM_wpDutyCycle : 32|8@1+ (1,0) [0|100] "Duty Cycle" Vector__XXX
 SG_ PDM_teensyTemp : 48|16@1- (0.1,0) [-5|100] "degC" Vector__XXX

BO_ 410 PDM_410: 8 PDM
 SG_ PDM_uptime : 0|32@1+ (1,0) [0|4294967295] "ms" Vector__XXX

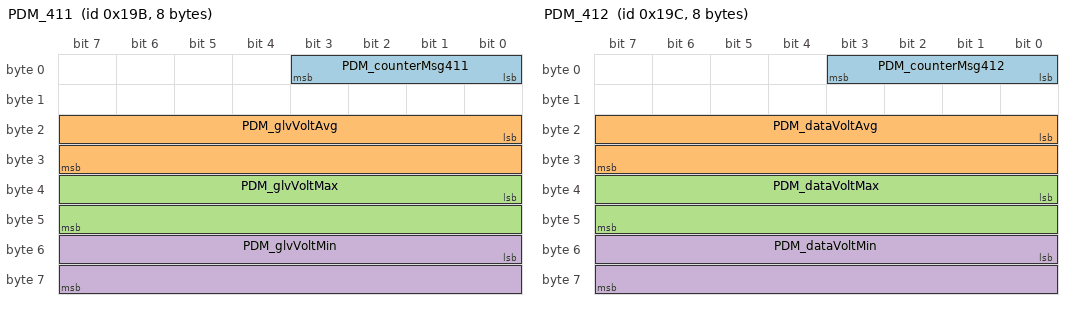
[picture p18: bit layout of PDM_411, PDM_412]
BO_ 411 PDM_411: 8 PDM
 SG_ PDM_counterMsg411 : 0|4@1+ (1,0) [0|15] "" Vector__XXX
 SG_ PDM_glvVoltAvg : 16|16@1- (0.001,0) [-5|20] "V" Vector__XXX
 SG_ PDM_glvVoltMax : 32|16@1- (0.001,0) [-5|20] "V" Vector__XXX
 SG_ PDM_glvVoltMin : 48|16@1- (0.001,0) [-5|20] "V" Vector__XXX

BO_ 412 PDM_412: 8 PDM
 SG_ PDM_counterMsg412 : 0|4@1+ (1,0) [0|15] "" Vector__XXX
 SG_ PDM_dataVoltAvg : 16|16@1- (0.001,0) [-5|20] "V" Vector__XXX
 SG_ PDM_dataVoltMax : 32|16@1- (0.001,0) [-5|20] "V" Vector__XXX
 SG_ PDM_dataVoltMin : 48|16@1- (0.001,0) [-5|20] "V" Vector__XXX

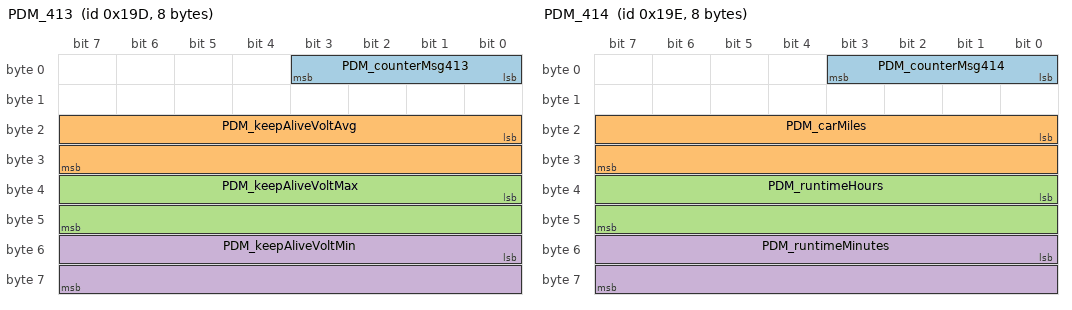
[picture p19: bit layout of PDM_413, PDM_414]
BO_ 413 PDM_413: 8 PDM
 SG_ PDM_counterMsg413 : 0|4@1+ (1,0) [0|15] "" Vector__XXX
 SG_ PDM_keepAliveVoltAvg : 16|16@1- (0.001,0) [-5|20] "V" Vector__XXX
 SG_ PDM_keepAliveVoltMax : 32|16@1- (0.001,0) [-5|20] "V" Vector__XXX
 SG_ PDM_keepAliveVoltMin : 48|16@1- (0.001,0) [-5|20] "V" Vector__XXX

BO_ 414 PDM_414: 8 PDM
 SG_ PDM_counterMsg414 : 0|4@1+ (1,0) [0|15] "" Vector__XXX
 SG_ PDM_carMiles : 16|16@1- (0.1,0) [-3276.8|3276.7] "mi" Vector__XXX
 SG_ PDM_runtimeHours : 32|16@1- (1,0) [-32768|32767] "hrs" Vector__XXX
 SG_ PDM_runtimeMinutes : 48|16@1- (1,0) [-32768|32767] "mins" Vector__XXX

BO_ 450 MM52_450: 8 MM52
 SG_ MM52_yawRate : 0|16@1+ (0.005,-163.9) [0|0] "deg/sec" Vector__XXX
 SG_ MM52_ay : 32|16@1+ (0.0001274,-4.1745795) [0|0] "g" Vector__XXX

BO_ 451 MM52_451: 8 MM52
 SG_ MM52_rollRate : 0|16@1+ (-0.005,163.9) [0|0] "deg/sec" Vector__XXX
 SG_ MM52_ax : 16|16@1+ (-0.0001274,4.1745795) [0|0] "g" Vector__XXX
 SG_ MM52_az : 32|16@1+ (-0.0001274,4.1745795) [0|0] "g" Vector__XXX

CM_ SG_ 150 VCU_counterMsg150 "Counter Message 150";
CM_ SG_ 150 VCU_throttlePosition "Final throttle position";
CM_ SG_ 150 VCU_throttlePosition1 "TPS1";
CM_ SG_ 150 VCU_throttlePosition2 "TPS2";
CM_ SG_ 151 VCU_counterMsg151 "Counter Message 151";
CM_ SG_ 151 VCU_brakeBias "Brake bias";
CM_ SG_ 151 VCU_brakePressureF "Front brake pressure";
CM_ SG_ 151 VCU_brakePressureR "Rear brake pressure";
CM_ SG_ 152 VCU_counterMsg152 "Counter Message 152";
CM_ SG_ 152 VCU_vehicleState "Vehicle state (enumerated in DBC value table)";
CM_ SG_ 152 VCU_torqueProfile "Torque profile (enumerated in DBC value table)";
CM_ SG_ 152 VCU_torqueCurve "Torque curve (enumerated in DBC value table)";
CM_ SG_ 152 VCU_rtmSound "Ready to move sound";
CM_ SG_ 153 VCU_counterMsg153 "Counter Message 153";
CM_ SG_ 153 VCU_startSwitch "Start switch signal";
CM_ SG_ 153 VCU_pwrUpSwitch "Power up switch signal";
CM_ SG_ 153 VCU_pwrDownSwitch "Power down switch signal";
CM_ SG_ 153 VCU_coolSwitch "Cool switch signal";
CM_ SG_ 154 VCU_counterMsg154 "Counter Message 154";
CM_ SG_ 154 VCU_tCActive "0 = off, 1 = on Enumeration";
CM_ SG_ 154 VCU_tCEnable "Enumeration";
CM_ SG_ 154 VCU_regenEnable "Enumeration";
CM_ SG_ 155 VCU_counterMsg155 "Counter Message 155";
CM_ SG_ 155 VCU_driveSpeed "Front wheel speed";
CM_ SG_ 155 VCU_assistedTorque "Torque after brake regen and TC";
CM_ SG_ 155 VCU_contactorFault "Signal to fire contactors to BMS (enumerated)";
CM_ SG_ 156 VCU_counterMsg156 "Counter Message 156";
CM_ SG_ 500 BMS_counterMsg500 "Counter Message 300";
CM_ SG_ 500 BMS_PackVoltage "BMS summed voltage of pack";
CM_ SG_ 500 BMS_PackCurrent "pack current from bms";
CM_ SG_ 500 BMS_PackSOC "state of charge calc from bms";
CM_ SG_ 501 BMS_counterMsg501 "Counter Message 301";
CM_ SG_ 501 BMS_Module1V "module 1 voltage";
CM_ SG_ 501 BMS_Module2V "module 2 voltage";
CM_ SG_ 501 BMS_Module3V "module 3 voltage";
CM_ SG_ 502 BMS_counterMsg502 "Counter Message 302";
CM_ SG_ 502 BMS_Module4V "module 4 voltage";
CM_ SG_ 502 BMS_Module5V "module 5 voltage";
CM_ SG_ 503 BMS_counterMsg503 "Counter Message 303";
CM_ SG_ 503 BMS_Module1seg1V "module 1 segment 1 voltage";
CM_ SG_ 503 BMS_Module1seg2V "module 1 segment 2 voltage";
CM_ SG_ 503 BMS_Module1seg3V "module 1 segment 3 voltage";
CM_ SG_ 504 BMS_counterMsg504 "Counter Message 304";
CM_ SG_ 504 BMS_Module1seg4V "module 1 segment 4 voltage";
CM_ SG_ 504 BMS_Module1seg5V "module 1 segment 5 voltage";
CM_ SG_ 504 BMS_Module1seg6V "module 1 segment 6 voltage";
CM_ SG_ 505 BMS_counterMsg505 "Counter Message 305";
CM_ SG_ 505 BMS_Module1seg7V "module 1 segment 7 voltage";
CM_ SG_ 505 BMS_Module1seg8V "module 1 segment 8 voltage";
CM_ SG_ 505 BMS_Module1seg9V "module 1 segment 9 voltage";
CM_ SG_ 506 BMS_counterMsg506 "Counter Message 306";
CM_ SG_ 506 BMS_Module1seg10V "module 1 segment 10 voltage";
CM_ SG_ 506 BMS_Module1seg11V "module 1 segment 11 voltage";
CM_ SG_ 506 BMS_Module1seg12V "module 1 segment 12 voltage";
CM_ SG_ 507 BMS_counterMsg507 "Counter Message 307";
CM_ SG_ 507 BMS_Module1seg13V "module 1 segment 13 voltage";
CM_ SG_ 507 BMS_Module1seg14V "module 1 segment 14 voltage";
CM_ SG_ 507 BMS_Module1seg15V "module 1 segment 15 voltage";
CM_ SG_ 508 BMS_counterMsg508 "Counter Message 308";
CM_ SG_ 508 BMS_Module1seg16V "module 1 segment 16 voltage";
CM_ SG_ 508 BMS_Module1seg17V "module 1 segment 17 voltage";
CM_ SG_ 508 BMS_Module1seg18V "module 1 segment 18 voltage";
CM_ SG_ 509 BMS_counterMsg509 "Counter Message 309";
CM_ SG_ 509 BMS_Module1seg1Temp "module 1 segment 1 temperature";
CM_ SG_ 509 BMS_Module1seg2Temp "module 1 segment 2 temperature";
CM_ SG_ 509 BMS_Module1seg3Temp "module 1 segment 3 temperature";
CM_ SG_ 510 BMS_counterMsg510 "Counter Message 310";
CM_ SG_ 510 BMS_Module1seg4Temp "module 1 segment 4 temperature";
CM_ SG_ 510 BMS_Module1seg5Temp "module 1 segment 5 temperature";
CM_ SG_ 510 BMS_Module1seg6Temp "module 1 segment 6 temperature";
CM_ SG_ 511 BMS_counterMsg511 "Counter Message 311";
CM_ SG_ 511 BMS_Module1seg7Temp "module 1 segment 7 temperature";
CM_ SG_ 511 BMS_Module1seg8Temp "module 1 segment 8 temperature";
CM_ SG_ 511 BMS_Module1seg9Temp "module 1 segment 9 temperature";
CM_ SG_ 512 BMS_counterMsg512 "Counter Message 312";
CM_ SG_ 512 BMS_Module1seg10Temp "module 1 segment 10 temperature";
CM_ SG_ 512 BMS_Module1seg11Temp "module 1 segment 11 temperature";
CM_ SG_ 512 BMS_Module1seg12Temp "module 1 segment 12 temperature";
CM_ SG_ 513 BMS_counterMsg513 "Counter Message 313";
CM_ SG_ 513 BMS_Module1seg13Temp "module 1 segment 13 temperature";
CM_ SG_ 513 BMS_Module1seg14Temp "module 1 segment 14 temperature";
CM_ SG_ 513 BMS_Module1seg15Temp "module 1 segment 15 temperature";
CM_ SG_ 514 BMS_counterMsg514 "Counter Message 314";
CM_ SG_ 514 BMS_Module1seg16Temp "module 1 segment 16 temperature";
CM_ SG_ 514 BMS_Module1seg17Temp "module 1 segment 17 temperature";
CM_ SG_ 514 BMS_Module1seg18Temp "module 1 segment 18 temperature";
CM_ SG_ 515 BMS_counterMsg515 "Counter Message 315";
CM_ SG_ 515 BMS_Module2seg1V "module 2 segment 1 voltage";
CM_ SG_ 515 BMS_Module2seg2V "module 2 segment 2 voltage";
CM_ SG_ 515 BMS_Module2seg3V "module 2 segment 3 voltage";
CM_ SG_ 516 BMS_counterMsg516 "Counter Message 316";
CM_ SG_ 516 BMS_Module2seg4V "module 2 segment 4 voltage";
CM_ SG_ 516 BMS_Module2seg5V "module 2 segment 5 voltage";
CM_ SG_ 516 BMS_Module2seg6V "module 2 segment 6 voltage";
CM_ SG_ 517 BMS_counterMsg517 "Counter Message 317";
CM_ SG_ 517 BMS_Module2seg7V "module 2 segment 7 voltage";
CM_ SG_ 517 BMS_Module2seg8V "module 2 segment 8 voltage";
CM_ SG_ 517 BMS_Module2seg9V "module 2 segment 9 voltage";
CM_ SG_ 518 BMS_counterMsg518 "Counter Message 318";
CM_ SG_ 518 BMS_Module2seg10V "module 2 segment 10 voltage";
CM_ SG_ 518 BMS_Module2seg11V "module 2 segment 11 voltage";
CM_ SG_ 518 BMS_Module2seg12V "module 2 segment 12 voltage";
CM_ SG_ 519 BMS_counterMsg519 "Counter Message 319";
CM_ SG_ 519 BMS_Module2seg13V "module 2 segment 13 voltage";
CM_ SG_ 519 BMS_Module2seg14V "module 2 segment 14 voltage";
CM_ SG_ 519 BMS_Module2seg15V "module 2 segment 15 voltage";
CM_ SG_ 520 BMS_counterMsg520 "Counter Message 320";
CM_ SG_ 520 BMS_Module2seg16V "module 2 segment 16 voltage";
CM_ SG_ 520 BMS_Module2seg17V "module 2 segment 17 voltage";
CM_ SG_ 520 BMS_Module2seg18V "module 2 segment 18 voltage";
CM_ SG_ 521 BMS_counterMsg521 "Counter Message 321";
CM_ SG_ 521 BMS_Module2seg1Temp "module 2 segment 1 temperature";
CM_ SG_ 521 BMS_Module2seg2Temp "module 2 segment 2 temperature";
CM_ SG_ 521 BMS_Module2seg3Temp "module 2 segment 3 temperature";
CM_ SG_ 522 BMS_counterMsg522 "Counter Message 322";
CM_ SG_ 522 BMS_Module2seg4Temp "module 2 segment 4 temperature";
CM_ SG_ 522 BMS_Module2seg5Temp "module 2 segment 5 temperature";
CM_ SG_ 522 BMS_Module2seg6Temp "module 2 segment 6 temperature";
CM_ SG_ 523 BMS_counterMsg523 "Counter Message 323";
CM_ SG_ 523 BMS_Module2seg7Temp "module 2 segment 7 temperature";
CM_ SG_ 523 BMS_Module2seg8Temp "module 2 segment 8 temperature";
CM_ SG_ 523 BMS_Module2seg9Temp "module 2 segment 9 temperature";
CM_ SG_ 524 BMS_counterMsg524 "Counter Message 324";
CM_ SG_ 524 BMS_Module2seg10Temp "module 2 segment 10 temperature";
CM_ SG_ 524 BMS_Module2seg11Temp "module 2 segment 11 temperature";
CM_ SG_ 524 BMS_Module2seg12Temp "module 2 segment 12 temperature";
CM_ SG_ 525 BMS_counterMsg525 "Counter Message 325";
CM_ SG_ 525 BMS_Module2seg13Temp "module 2 segment 13 temperature";
CM_ SG_ 525 BMS_Module2seg14Temp "module 2 segment 14 temperature";
CM_ SG_ 525 BMS_Module2seg15Temp "module 2 segment 15 temperature";
CM_ SG_ 526 BMS_counterMsg526 "Counter Message 326";
CM_ SG_ 526 BMS_Module2seg16Temp "module 2 segment 16 temperature";
CM_ SG_ 526 BMS_Module2seg17Temp "module 2 segment 17 temperature";
CM_ SG_ 526 BMS_Module2seg18Temp "module 2 segment 18 temperature";
CM_ SG_ 527 BMS_counterMsg527 "Counter Message 327";
CM_ SG_ 527 BMS_Module3seg1V "module 3 segment 1 voltage";
CM_ SG_ 527 BMS_Module3seg2V "module 3 segment 2 voltage";
CM_ SG_ 527 BMS_Module3seg3V "module 3 segment 3 voltage";
CM_ SG_ 528 BMS_counterMsg528 "Counter Message 328";
CM_ SG_ 528 BMS_Module3seg4V "module 3 segment 4 voltage";
CM_ SG_ 528 BMS_Module3seg5V "module 3 segment 5 voltage";
CM_ SG_ 528 BMS_Module3seg6V "module 3 segment 6 voltage";
CM_ SG_ 529 BMS_counterMsg529 "Counter Message 329";
CM_ SG_ 529 BMS_Module3seg7V "module 3 segment 7 voltage";
CM_ SG_ 529 BMS_Module3seg8V "module 3 segment 8 voltage";
CM_ SG_ 529 BMS_Module3seg9V "module 3 segment 9 voltage";
CM_ SG_ 530 BMS_counterMsg530 "Counter Message 330";
CM_ SG_ 530 BMS_Module3seg10V "module 3 segment 10 voltage";
CM_ SG_ 530 BMS_Module3seg11V "module 3 segment 11 voltage";
CM_ SG_ 530 BMS_Module3seg12V "module 3 segment 12 voltage";
CM_ SG_ 531 BMS_counterMsg531 "Counter Message 331";
CM_ SG_ 531 BMS_Module3seg13V "module 3 segment 13 voltage";
CM_ SG_ 531 BMS_Module3seg14V "module 3 segment 14 voltage";
CM_ SG_ 531 BMS_Module3seg15V "module 3 segment 15 voltage";
CM_ SG_ 532 BMS_counterMsg532 "Counter Message 332";
CM_ SG_ 532 BMS_Module3seg16V "module 3 segment 16 voltage";
CM_ SG_ 532 BMS_Module3seg17V "module 3 segment 17 voltage";
CM_ SG_ 532 BMS_Module3seg18V "module 3 segment 18 voltage";
CM_ SG_ 533 BMS_counterMsg533 "Counter Message 333";
CM_ SG_ 533 BMS_Module3seg1Temp "module 3 segment 1 temperature";
CM_ SG_ 533 BMS_Module3seg2Temp "module 3 segment 2 temperature";
CM_ SG_ 533 BMS_Module3seg3Temp "module 3 segment 3 temperature";
CM_ SG_ 534 BMS_counterMsg534 "Counter Message 334";
CM_ SG_ 534 BMS_Module3seg4Temp "module 3 segment 4 temperature";
CM_ SG_ 534 BMS_Module3seg5Temp "module 3 segment 5 temperature";
CM_ SG_ 534 BMS_Module3seg6Temp "module 3 segment 6 temperature";
CM_ SG_ 535 BMS_counterMsg535 "Counter Message 335";
CM_ SG_ 535 BMS_Module3seg7Temp "module 3 segment 7 temperature";
CM_ SG_ 535 BMS_Module3seg8Temp "module 3 segment 8 temperature";
CM_ SG_ 535 BMS_Module3seg9Temp "module 3 segment 9 temperature";
CM_ SG_ 536 BMS_counterMsg536 "Counter Message 336";
CM_ SG_ 536 BMS_Module3seg10Temp "module 3 segment 10 temperature";
CM_ SG_ 536 BMS_Module3seg11Temp "module 3 segment 11 temperature";
CM_ SG_ 536 BMS_Module3seg12Temp "module 3 segment 12 temperature";
CM_ SG_ 537 BMS_counterMsg537 "Counter Message 337";
CM_ SG_ 537 BMS_Module3seg13Temp "module 3 segment 13 temperature";
CM_ SG_ 537 BMS_Module3seg14Temp "module 3 segment 14 temperature";
CM_ SG_ 537 BMS_Module3seg15Temp "module 3 segment 15 temperature";
CM_ SG_ 538 BMS_counterMsg538 "Counter Message 338";
CM_ SG_ 538 BMS_Module3seg16Temp "module 3 segment 16 temperature";
CM_ SG_ 538 BMS_Module3seg17Temp "module 3 segment 17 temperature";
CM_ SG_ 538 BMS_Module3seg18Temp "module 3 segment 18 temperature";
CM_ SG_ 539 BMS_counterMsg539 "Counter Message 339";
CM_ SG_ 539 BMS_Module4seg1V "module 4 segment 1 voltage";
CM_ SG_ 539 BMS_Module4seg2V "module 4 segment 2 voltage";
CM_ SG_ 539 BMS_Module4seg3V "module 4 segment 3 voltage";
CM_ SG_ 540 BMS_counterMsg540 "Counter Message 340";
CM_ SG_ 540 BMS_Module4seg4V "module 4 segment 4 voltage";
CM_ SG_ 540 BMS_Module4seg5V "module 4 segment 5 voltage";
CM_ SG_ 540 BMS_Module4seg6V "module 4 segment 6 voltage";
CM_ SG_ 541 BMS_counterMsg541 "Counter Message 341";
CM_ SG_ 541 BMS_Module4seg7V "module 4 segment 7 voltage";
CM_ SG_ 541 BMS_Module4seg8V "module 4 segment 8 voltage";
CM_ SG_ 541 BMS_Module4seg9V "module 4 segment 9 voltage";
CM_ SG_ 542 BMS_counterMsg542 "Counter Message 342";
CM_ SG_ 542 BMS_Module4seg10V "module 4 segment 10 voltage";
CM_ SG_ 542 BMS_Module4seg11V "module 4 segment 11 voltage";
CM_ SG_ 542 BMS_Module4seg12V "module 4 segment 12 voltage";
CM_ SG_ 543 BMS_counterMsg543 "Counter Message 343";
CM_ SG_ 543 BMS_Module4seg13V "module 4 segment 13 voltage";
CM_ SG_ 543 BMS_Module4seg14V "module 4 segment 14 voltage";
CM_ SG_ 543 BMS_Module4seg15V "module 4 segment 15 voltage";
CM_ SG_ 544 BMS_counterMsg544 "Counter Message 344";
CM_ SG_ 544 BMS_Module4seg16V "module 4 segment 16 voltage";
CM_ SG_ 544 BMS_Module4seg17V "module 4 segment 17 voltage";
CM_ SG_ 544 BMS_Module4seg18V "module 4 segment 18 voltage";
CM_ SG_ 545 BMS_counterMsg545 "Counter Message 345";
CM_ SG_ 545 BMS_Module4seg1Temp "module 4 segment 1 temperature";
CM_ SG_ 545 BMS_Module4seg2Temp "module 4 segment 2 temperature";
CM_ SG_ 545 BMS_Module4seg3Temp "module 4 segment 3 temperature";
CM_ SG_ 546 BMS_counterMsg546 "Counter Message 346";
CM_ SG_ 546 BMS_Module4seg4Temp "module 4 segment 4 temperature";
CM_ SG_ 546 BMS_Module4seg5Temp "module 4 segment 5 temperature";
CM_ SG_ 546 BMS_Module4seg6Temp "module 4 segment 6 temperature";
CM_ SG_ 547 BMS_counterMsg547 "Counter Message 347";
CM_ SG_ 547 BMS_Module4seg7Temp "module 4 segment 7 temperature";
CM_ SG_ 547 BMS_Module4seg8Temp "module 4 segment 8 temperature";
CM_ SG_ 547 BMS_Module4seg9Temp "module 4 segment 9 temperature";
CM_ SG_ 548 BMS_counterMsg548 "Counter Message 348";
CM_ SG_ 548 BMS_Module4seg10Temp "module 4 segment 10 temperature";
CM_ SG_ 548 BMS_Module4seg11Temp "module 4 segment 11 temperature";
CM_ SG_ 548 BMS_Module4seg12Temp "module 4 segment 12 temperature";
CM_ SG_ 549 BMS_counterMsg549 "Counter Message 349";
CM_ SG_ 549 BMS_Module4seg13Temp "module 4 segment 13 temperature";
CM_ SG_ 549 BMS_Module4seg14Temp "module 4 segment 14 temperature";
CM_ SG_ 549 BMS_Module4seg15Temp "module 4 segment 15 temperature";
CM_ SG_ 550 BMS_counterMsg550 "Counter Message 350";
CM_ SG_ 550 BMS_Module4seg16Temp "module 4 segment 16 temperature";
CM_ SG_ 550 BMS_Module4seg17Temp "module 4 segment 17 temperature";
CM_ SG_ 550 BMS_Module4seg18Temp "module 4 segment 18 temperature";
CM_ SG_ 551 BMS_counterMsg551 "Counter Message 351";
CM_ SG_ 551 BMS_Module5seg1V "module 5 segment 1 voltage";
CM_ SG_ 551 BMS_Module5seg2V "module 5 segment 2 voltage";
CM_ SG_ 551 BMS_Module5seg3V "module 5 segment 3 voltage";
CM_ SG_ 552 BMS_counterMsg552 "Counter Message 352";
CM_ SG_ 552 BMS_Module5seg4V "module 5 segment 4 voltage";
CM_ SG_ 552 BMS_Module5seg5V "module 5 segment 5 voltage";
CM_ SG_ 552 BMS_Module5seg6V "module 5 segment 6 voltage";
CM_ SG_ 553 BMS_counterMsg553 "Counter Message 353";
CM_ SG_ 553 BMS_Module5seg7V "module 5 segment 7 voltage";
CM_ SG_ 553 BMS_Module5seg8V "module 5 segment 8 voltage";
CM_ SG_ 553 BMS_Module5seg9V "module 5 segment 9 voltage";
CM_ SG_ 554 BMS_counterMsg554 "Counter Message 354";
CM_ SG_ 554 BMS_Module5seg10V "module 5 segment 10 voltage";
CM_ SG_ 554 BMS_Module5seg11V "module 5 segment 11 voltage";
CM_ SG_ 554 BMS_Module5seg12V "module 5 segment 12 voltage";
CM_ SG_ 555 BMS_counterMsg555 "Counter Message 355";
CM_ SG_ 555 BMS_Module5seg13V "module 5 segment 13 voltage";
CM_ SG_ 555 BMS_Module5seg14V "module 5 segment 14 voltage";
CM_ SG_ 555 BMS_Module5seg15V "module 5 segment 15 voltage";
CM_ SG_ 556 BMS_counterMsg556 "Counter Message 356";
CM_ SG_ 556 BMS_Module5seg16V "module 5 segment 16 voltage";
CM_ SG_ 556 BMS_Module5seg17V "module 5 segment 17 voltage";
CM_ SG_ 556 BMS_Module5seg18V "module 5 segment 18 voltage";
CM_ SG_ 557 BMS_counterMsg557 "Counter Message 357";
CM_ SG_ 557 BMS_Module5seg1Temp "module 5 segment 1 temperature";
CM_ SG_ 557 BMS_Module5seg2Temp "module 5 segment 2 temperature";
CM_ SG_ 557 BMS_Module5seg3Temp "module 5 segment 3 temperature";
CM_ SG_ 558 BMS_counterMsg558 "Counter Message 358";
CM_ SG_ 558 BMS_Module5seg4Temp "module 5 segment 4 temperature";
CM_ SG_ 558 BMS_Module5seg5Temp "module 5 segment 5 temperature";
CM_ SG_ 558 BMS_Module5seg6Temp "module 5 segment 6 temperature";
CM_ SG_ 559 BMS_counterMsg559 "Counter Message 359";
CM_ SG_ 559 BMS_Module5seg7Temp "module 5 segment 7 temperature";
CM_ SG_ 559 BMS_Module5seg8Temp "module 5 segment 8 temperature";
CM_ SG_ 559 BMS_Module5seg9Temp "module 5 segment 9 temperature";
CM_ SG_ 560 BMS_counterMsg560 "Counter Message 360";
CM_ SG_ 560 BMS_Module5seg10Temp "module 5 segment 10 temperature";
CM_ SG_ 560 BMS_Module5seg11Temp "module 5 segment 11 temperature";
CM_ SG_ 560 BMS_Module5seg12Temp "module 5 segment 12 temperature";
CM_ SG_ 561 BMS_counterMsg561 "Counter Message 361";
CM_ SG_ 561 BMS_Module5seg13Temp "module 5 segment 13 temperature";
CM_ SG_ 561 BMS_Module5seg14Temp "module 5 segment 14 temperature";
CM_ SG_ 561 BMS_Module5seg15Temp "module 5 segment 15 temperature";
CM_ SG_ 562 BMS_counterMsg562 "Counter Message 362";
CM_ SG_ 562 BMS_Module5seg16Temp "module 5 segment 16 temperature";
CM_ SG_ 562 BMS_Module5seg17Temp "module 5 segment 17 temperature";
CM_ SG_ 562 BMS_Module5seg18Temp "module 5 segment 18 temperature";
CM_ SG_ 250 DD_counterMsg250 "Counter Message 250";
CM_ SG_ 250 DD_boardTemp "Board Temp";
CM_ SG_ 250 DD_teensyTemp "Teensy Board Temp";
CM_ SG_ 372 MM5_yawRate "Yaw Rate";
CM_ SG_ 372 MM5_ay "Acceleration Y Axis";
CM_ SG_ 376 MM5_rollRate "Roll Rate";
CM_ SG_ 376 MM5_ax "Acceleration X Axis";
CM_ SG_ 380 MM5_az "Acceleration Z Axis";
CM_ SG_ 400 PDM_counterMsg400 "Counter Message 400";
CM_ SG_ 400 PDM_boardTemp "Board Temperature";
CM_ SG_ 400 PDM_brakelightVoltAvg "Brakelight Average Voltage";
CM_ SG_ 400 PDM_vehicleState "0 = off, 1 = on, 2 = cooldown";
CM_ SG_ 400 PDM_coolingOverrideActive "Cooling Override State";
CM_ SG_ 401 PDM_counterMsg401 "Counter Message 401";
CM_ SG_ 401 PDM_pdmCurrentAvg "PDM Average Current";
CM_ SG_ 401 PDM_pdmCurrentMax "PDM Maximum Current";
CM_ SG_ 401 PDM_pdmCurrentMin "PDM Minimum Current";
CM_ SG_ 402 PDM_counterMsg402 "Counter Message 402";
CM_ SG_ 402 PDM_pdmVoltAvg "PDM Average Voltage";
CM_ SG_ 402 PDM_pdmVoltMax "PDM Maximum Voltage";
CM_ SG_ 402 PDM_pdmVoltMin "PDM Minimum Voltage";
CM_ SG_ 403 PDM_counterMsg403 "Counter Message 403";
CM_ SG_ 403 PDM_fanRightCurrentAvg "Right Fan Average Current";
CM_ SG_ 403 PDM_fanRightCurrentMax "Right Fan Maximum Current";
CM_ SG_ 403 PDM_fanRightCurrentMin "Right Fan Minimum Current";
CM_ SG_ 404 PDM_counterMsg404 "Counter Message 404";
CM_ SG_ 404 PDM_fanRightVoltAvg "Right Fan Average Voltage";
CM_ SG_ 404 PDM_fanRightVoltMax "Right Fan Maximum Voltage";
CM_ SG_ 404 PDM_fanRightVoltMin "Right Fan Minimum Voltage";
CM_ SG_ 405 PDM_counterMsg405 "Counter Message 405";
CM_ SG_ 405 PDM_fanLeftCurrentAvg "Left Fan Average Current";
CM_ SG_ 405 PDM_fanLeftCurrentMax "Left Fan Maximum Current";
CM_ SG_ 405 PDM_fanLeftCurrentMin "Left Fan Minimum Current";
CM_ SG_ 406 PDM_counterMsg406 "Counter Message 406";
CM_ SG_ 406 PDM_fanLeftVoltAvg "Left Fan Average Voltage";
CM_ SG_ 406 PDM_fanLeftVoltMax "Left Fan Maximum Voltage";
CM_ SG_ 406 PDM_fanLeftVoltMin "Left Fan Minimum Voltage";
CM_ SG_ 407 PDM_counterMsg407 "Counter Message 407";
CM_ SG_ 407 PDM_wpCurrentAvg "Water Pump Average Current";
CM_ SG_ 407 PDM_wpCurrentMax "Water Pump Maximum Current";
CM_ SG_ 407 PDM_wpCurrentMin "Water Pump Minimum Current";
CM_ SG_ 408 PDM_counterMsg408 "Counter Message 408";
CM_ SG_ 408 PDM_wpVoltAvg "Water Pump Average Voltage";
CM_ SG_ 408 PDM_wpVoltMax "Water Pump Maximum Voltage";
CM_ SG_ 408 PDM_wpVoltMin "Water Pump Minimum Voltage";
CM_ SG_ 409 PDM_counterMsg409 "Counter Message 409";
CM_ SG_ 409 PDM_fanLeftDutyCycle "Left Fan Duty Cycle";
CM_ SG_ 409 PDM_fanRightDutyCycle "Right Fan Duty Cycle";
CM_ SG_ 409 PDM_wpDutyCycle "Water Pump Duty Cycle";
CM_ SG_ 409 PDM_teensyTemp "Teensy Board Temperature";
CM_ SG_ 410 PDM_uptime "PDM Teensy Uptime";
CM_ SG_ 411 PDM_counterMsg411 "Counter Message 411";
CM_ SG_ 411 PDM_glvVoltAvg "GLV Average Voltage";
CM_ SG_ 411 PDM_glvVoltMax "GLV Maximum Voltage";
CM_ SG_ 411 PDM_glvVoltMin "GLV Minimum Voltage";
CM_ SG_ 412 PDM_counterMsg412 "Counter Message 412";
CM_ SG_ 412 PDM_dataVoltAvg "Data Average Voltage";
CM_ SG_ 412 PDM_dataVoltMax "Data Maximum Voltage";
CM_ SG_ 412 PDM_dataVoltMin "Data Minimum Voltage";
CM_ SG_ 413 PDM_counterMsg413 "Counter Message 413";
CM_ SG_ 413 PDM_keepAliveVoltAvg "Keep Alive Average Voltage";
CM_ SG_ 413 PDM_keepAliveVoltMax "Keep Alive Maximum Voltage";
CM_ SG_ 413 PDM_keepAliveVoltMin "Keep Alive Minimum Voltage";
CM_ SG_ 414 PDM_counterMsg414 "Counter Message 414";
CM_ SG_ 414 PDM_carMiles "Car Miles";
CM_ SG_ 414 PDM_runtimeHours "Runtime Hours";
CM_ SG_ 414 PDM_runtimeMinutes "Runtime Minutes";
CM_ SG_ 450 MM52_yawRate "Yaw Rate";
CM_ SG_ 450 MM52_ay "Acceleration Y Axis";
CM_ SG_ 451 MM52_rollRate "Roll Rate";
CM_ SG_ 451 MM52_ax "Acceleration X Axis";
CM_ SG_ 451 MM52_az "Acceleration Z Axis";

BA_DEF_  "BusType" STRING ;
BA_DEF_DEF_  "BusType" "CAN";
